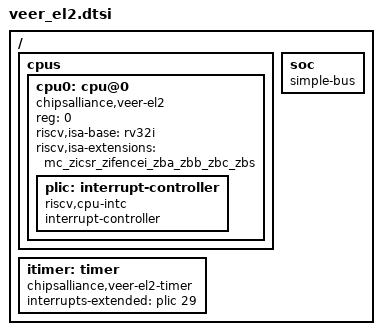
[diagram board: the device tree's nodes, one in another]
// Copyright (c) 2026 Antmicro
// SPDX-License-Identifier: Apache-2.0

/ {
	#address-cells = <1>;
	#size-cells = <1>;

	cpus {
		#address-cells = <1>;
		#size-cells = <0>;

		cpu0: cpu@0 {
			device_type = "cpu";
			compatible = "chipsalliance,veer-el2", "riscv";
			reg = <0>;
			riscv,isa-base = "rv32i";
			riscv,isa-extensions = "mc_zicsr_zifencei_zba_zbb_zbc_zbs";

			plic: interrupt-controller {
				compatible = "riscv,cpu-intc";
				#address-cells = <0>;
				#interrupt-cells = <1>;
				interrupt-controller;
			};
		};
	};

	itimer: timer {
		compatible = "chipsalliance,veer-el2-timer";
		interrupts-extended = <&plic 29>;
		status = "okay";
	};

	soc {
		#address-cells = <1>;
		#size-cells = <1>;
		compatible = "simple-bus";
		ranges;
	};
};
